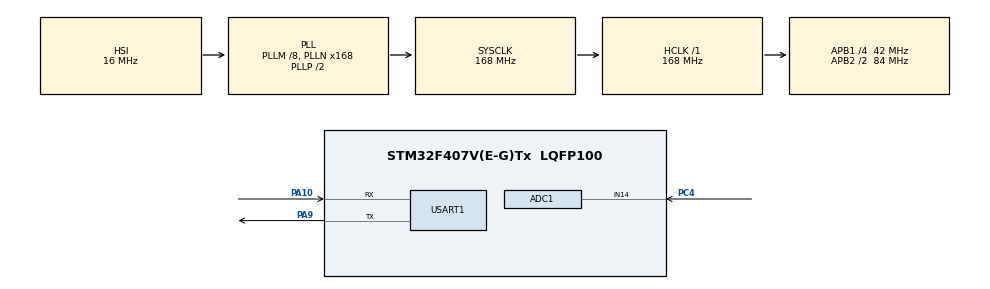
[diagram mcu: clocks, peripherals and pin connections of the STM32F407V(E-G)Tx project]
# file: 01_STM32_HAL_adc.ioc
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ADC1.Channel-0\#ChannelRegularConversion=ADC_CHANNEL_TEMPSENSOR
ADC1.Channel-1\#ChannelRegularConversion=ADC_CHANNEL_14
ADC1.ExternalTrigConv=ADC_SOFTWARE_START
ADC1.InjNumberOfConversion=0
ADC1.NbrOfConversion=2
ADC1.NbrOfConversionFlag=1
ADC1.Rank-0\#ChannelRegularConversion=1
ADC1.Rank-1\#ChannelRegularConversion=2
ADC1.SamplingTime-0\#ChannelRegularConversion=ADC_SAMPLETIME_112CYCLES
ADC1.SamplingTime-1\#ChannelRegularConversion=ADC_SAMPLETIME_112CYCLES
ADC1.master=1
Mcu.Family=STM32F4
Mcu.Name=STM32F407V(E-G)Tx
Mcu.Package=LQFP100
NVIC.PriorityGroup=NVIC_PRIORITYGROUP_4
NVIC.USART1_IRQn=true\:0\:0\:false\:false\:true\:true\:true\:true
PA10.Mode=Asynchronous
PA10.Signal=USART1_RX
PA9.Mode=Asynchronous
PA9.Signal=USART1_TX
PC4.Signal=ADCx_IN14
ProjectManager.HeapSize=0x200
ProjectManager.StackSize=0x400
ProjectManager.TargetToolchain=MDK-ARM V5.32
RCC.48MHZClocksFreq_Value=84000000
RCC.AHBFreq_Value=168000000
RCC.APB1CLKDivider=RCC_HCLK_DIV4
RCC.APB1Freq_Value=42000000
RCC.APB1TimFreq_Value=84000000
RCC.APB2CLKDivider=RCC_HCLK_DIV2
RCC.APB2Freq_Value=84000000
RCC.APB2TimFreq_Value=168000000
RCC.CortexFreq_Value=168000000
RCC.HCLKFreq_Value=168000000
RCC.HSE_VALUE=25000000
RCC.HSI_VALUE=16000000
RCC.LSE_VALUE=32768
RCC.PLLM=8
RCC.PLLN=168
RCC.SYSCLKFreq_VALUE=168000000
RCC.SYSCLKSource=RCC_SYSCLKSOURCE_PLLCLK
RCC.VCOOutputFreq_Value=336000000
SH.ADCx_IN14.0=ADC1_IN14,IN14
USART1.VirtualMode=VM_ASYNC
VP_ADC1_TempSens_Input.Mode=IN-TempSens
board=custom

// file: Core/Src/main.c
/* USER CODE BEGIN Header */
/*********************************************

                   _ooOoo_
                  o8888888o
                  88" . "88
                  (| -_- |)
                  O\  =  /O
               ____/`---'\____
             .'  \\|     |//  `.
            /  \\|||  :  |||//  \
           /  _||||| -:- |||||-  \
           |   | \\\  -  /// |   |
           | \_|  ''\---/''  |   |
           \  .-\__  `-`  ___/-. /
         ___`. .'  /--.--\  `. . __
      ."" '<  `.___\_<|>_/___.'  >'"".
     | | :  `- \`.;`\ _ /`;.`/ - ` : | |
     \  \ `-.   \_ __\ /__ _/   .-` /  /
======`-.____`-.___\_____/___.-`____.-'======
                   `=---='
^^^^^^^^^^^^^^^^^^^^^^^^^^^^^^^^^^^^^^^^^^^^^
         佛祖保佑       永无BUG

**********************************************/
/* USER CODE END Header */
#include "main.h"
#include "adc.h"
#include "usart.h"
#include "gpio.h"

/* USER CODE BEGIN Includes */
#include <stdio.h>
int fputc(int ch, FILE* f) {
	HAL_UART_Transmit(&huart1, (uint8_t *)&ch,1, 0xFFFF);
	return ch;
}

/* USER CODE END Includes */

void SystemClock_Config(void);

int main(void)
{

  /* MCU Configuration--------------------------------------------------------*/

  /* Reset of all peripherals, Initializes the Flash interface and the Systick. */
  HAL_Init();

  /* Configure the system clock */
  SystemClock_Config();

  /* Initialize all configured peripherals */
  MX_GPIO_Init();
  MX_ADC1_Init();
  MX_USART1_UART_Init();
  /* USER CODE BEGIN 2 */

  printf("Init Complete!\n");

  /* USER CODE END 2 */

  /* Infinite loop */
  /* USER CODE BEGIN WHILE */
  while (1)
  {
    // 1. 开始采样 ------------------- 芯片温度
    HAL_ADC_Start(&hadc1);
    // 2. 等待采样完成
    while(HAL_OK != HAL_ADC_PollForConversion(&hadc1, HAL_MAX_DELAY));
    // 3. 读取采样结果
    uint16_t value = HAL_ADC_GetValue(&hadc1);
    // 将ADC数值转成温度值
    // ADC数值 -> 电压值 ( Vtemp / 3.3 = adc_val / 4095)
    float Vtemp = value * 3.3  / 4095;
    // 将电压值转化为温度值
    float temperature = ((1.45f - Vtemp) * 1000.0f / 4.1f) + 25;
    printf("temp: %d\t %5.2f ℃\r\n", value, temperature);

    // 2. 等待采样完成 ------------------- 电位器 IN14
    while(HAL_OK != HAL_ADC_PollForConversion(&hadc1, HAL_MAX_DELAY));
    // 3. 读取采样结果
    value = HAL_ADC_GetValue(&hadc1);
    // 将ADC数值转成温度值
    // ADC数值 -> 电压值 ( Vtemp / 3.3 = adc_val / 4095)
    float Voltage = value * 3.3  / 4095;
    printf("Voltage: %d\t %5.2f V\r\n", value, Voltage);

    HAL_Delay(200);

    /* USER CODE END WHILE */

  }
}

void SystemClock_Config(void)
{
  RCC_OscInitTypeDef RCC_OscInitStruct = {0};
  RCC_ClkInitTypeDef RCC_ClkInitStruct = {0};

  /** Configure the main internal regulator output voltage
  */
  __HAL_RCC_PWR_CLK_ENABLE();
  __HAL_PWR_VOLTAGESCALING_CONFIG(PWR_REGULATOR_VOLTAGE_SCALE1);

  /** Initializes the RCC Oscillators according to the specified parameters
  * in the RCC_OscInitTypeDef structure.
  */
  RCC_OscInitStruct.OscillatorType = RCC_OSCILLATORTYPE_HSI;
  RCC_OscInitStruct.HSIState = RCC_HSI_ON;
  RCC_OscInitStruct.HSICalibrationValue = RCC_HSICALIBRATION_DEFAULT;
  RCC_OscInitStruct.PLL.PLLState = RCC_PLL_ON;
  RCC_OscInitStruct.PLL.PLLSource = RCC_PLLSOURCE_HSI;
  RCC_OscInitStruct.PLL.PLLM = 8;
  RCC_OscInitStruct.PLL.PLLN = 168;
  RCC_OscInitStruct.PLL.PLLP = RCC_PLLP_DIV2;
  RCC_OscInitStruct.PLL.PLLQ = 4;
  if (HAL_RCC_OscConfig(&RCC_OscInitStruct) != HAL_OK)
  {
    Error_Handler();
  }

  /** Initializes the CPU, AHB and APB buses clocks
  */
  RCC_ClkInitStruct.ClockType = RCC_CLOCKTYPE_HCLK|RCC_CLOCKTYPE_SYSCLK
                              |RCC_CLOCKTYPE_PCLK1|RCC_CLOCKTYPE_PCLK2;
  RCC_ClkInitStruct.SYSCLKSource = RCC_SYSCLKSOURCE_PLLCLK;
  RCC_ClkInitStruct.AHBCLKDivider = RCC_SYSCLK_DIV1;
  RCC_ClkInitStruct.APB1CLKDivider = RCC_HCLK_DIV4;
  RCC_ClkInitStruct.APB2CLKDivider = RCC_HCLK_DIV2;

  if (HAL_RCC_ClockConfig(&RCC_ClkInitStruct, FLASH_LATENCY_5) != HAL_OK)
  {
    Error_Handler();
  }
}

void Error_Handler(void)
{
  __disable_irq();
  while (1)
  {
  }
}
